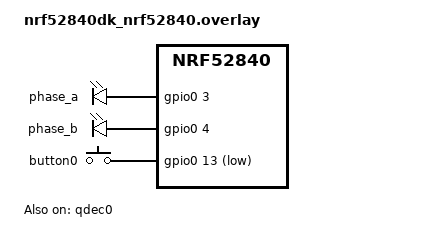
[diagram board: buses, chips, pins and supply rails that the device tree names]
/*
 * Copyright 2023 Nordic Semiconductor ASA
 * SPDX-License-Identifier: Apache-2.0
 */

/ {
	aliases {
		qdec0 = &qdec0;
		qenca = &phase_a;
		qencb = &phase_b;
	};

	encoder-emulate {
		compatible = "gpio-leds";
		phase_a: phase_a {
			/* Arduino A0 */
			gpios = <&gpio0 3 GPIO_ACTIVE_HIGH>;
		};
		phase_b: phase_b {
			/* Arduino A1 */
			gpios = <&gpio0 4 GPIO_ACTIVE_HIGH>;
		};
	};

};

&pinctrl {
	qdec_pinctrl: qdec_pinctrl {
		group1 {
			psels = <NRF_PSEL(QDEC_A, 0, 31)>,   /* Ardiuno A5 */
				<NRF_PSEL(QDEC_B, 0, 30)>;   /* Arduino A4 */
		};
	};
};

&qdec0 {
	status = "okay";
	pinctrl-0 = <&qdec_pinctrl>;
	pinctrl-names = "default";
	steps = < 20 >;
	led-pre = < 0 >;
};

&button0 {
};

&button0 {
	gpios = <&gpio0 11 (GPIO_ACTIVE_LOW | GPIO_PULL_UP)>;
};

&button0 {
	gpios = <&gpio0 11 (GPIO_ACTIVE_LOW | GPIO_PULL_DOWN)>;
};

&button0 {
	gpios = <&gpio0 11 GPIO_ACTIVE_LOW>;
};

&button0 {
	gpios = <&gpio0 13 GPIO_ACTIVE_LOW>;
};

&button0 {
	gpios = <&gpio0 13 (GPIO_ACTIVE_LOW | GPIO_PULL_UP)>;
};
